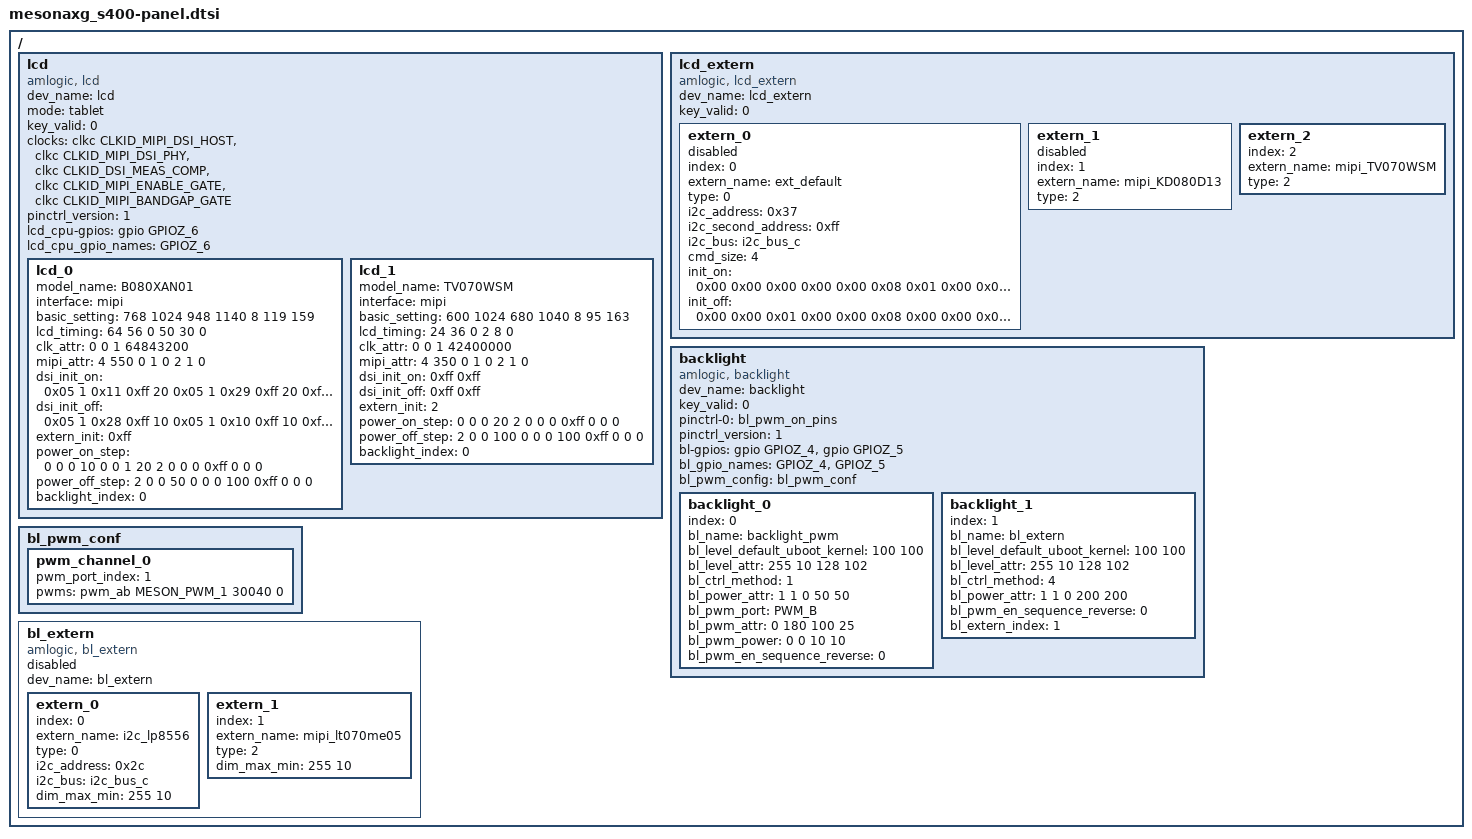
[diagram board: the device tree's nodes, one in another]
/*
 * arch/arm64/boot/dts/amlogic/mesongxm_q200-panel.dtsi
 *
 * Copyright (C) 2016 Amlogic, Inc. All rights reserved.
 *
 * This program is free software; you can redistribute it and/or modify
 * it under the terms of the GNU General Public License as published by
 * the Free Software Foundation; either version 2 of the License, or
 * (at your option) any later version.
 *
 * This program is distributed in the hope that it will be useful, but WITHOUT
 * ANY WARRANTY; without even the implied warranty of MERCHANTABILITY or
 * FITNESS FOR A PARTICULAR PURPOSE.  See the GNU General Public License for
 * more details.
 *
 */

/ {
	lcd{
		compatible = "amlogic, lcd";
		dev_name = "lcd";
		mode = "tablet";
		status = "okay";
		key_valid = <0>;
		clocks = <&clkc CLKID_MIPI_DSI_HOST
			&clkc CLKID_MIPI_DSI_PHY
			&clkc CLKID_DSI_MEAS_COMP
			&clkc CLKID_MIPI_ENABLE_GATE
			&clkc CLKID_MIPI_BANDGAP_GATE>;
		clock-names = "dsi_host",
			"dsi_phy",
			"dsi_meas",
			"mipi_enable_gate",
			"mipi_bandgap_gate";
		pinctrl_version = <1>; /* for uboot */

		/* power type:
		 *    (0=cpu_gpio, 1=pmu_gpio, 2=signal,3=extern, 0xff=ending)
		 * power index:
		 *    (point gpios_index, or extern_index,0xff=invalid)
		 * power value:(0=output low, 1=output high, 2=input)
		 * power delay:(unit in ms)
		 */
		lcd_cpu-gpios = <&gpio GPIOZ_6 GPIO_ACTIVE_HIGH>;
		lcd_cpu_gpio_names = "GPIOZ_6";

		lcd_0{
			model_name = "B080XAN01";
				/*interface(ttl,lvds,mipi)*/
			interface = "mipi";
				/* basic_setting:
				 * h_active,v_active,h_period,v_period,
				 * lcd_bits,screen_widht,screen_height
				 */
			basic_setting = <768 1024 948 1140 8 119 159>;
				/* lcd_timing:
				 * hs_width,hs_bp,hs_pol,vs_width,vs_bp,vs_pol
				 */
			lcd_timing = <64 56 0 50 30 0>;
				/* clk_attr:
				 * fr_adj_type(0=clock,1=htotal,2=vtotal),
				 * clk_ss_level,clk_auto_generate,
				 * pixel_clk(unit in Hz)
				 */
			clk_attr = <0 0 1 64843200>;
				/* mipi_attr:
				 * lane_num, bit_rate_max(MHz),
				 * factor(*100, default 0 for auto),
				 * operation_mode_init(0=video, 1=command),
				 * operation_mode_display(0=video, 1=command),
				 * video_mode_type
				 *     (0=sync_pulse,1=sync_event,2=burst),
				 * clk_lp_continuous(0=stop,1=continue),
				 * phy_stop_wait(0=auto,1=standard,2=slow)
				 */
			mipi_attr = <4 550 0 1 0 2 1 0>;
				/* dsi_init: data_type, num, data... */
			dsi_init_on = <0x05 1 0x11
					0xff 20     /* delay(ms) */
					0x05 1 0x29
					0xff 20     /* delay(ms) */
					0xff 0xff>; /* ending flag */
			dsi_init_off = <0x05 1 0x28
					0xff 10     /* delay(ms) */
					0x05 1 0x10
					0xff 10     /* delay(ms) */
					0xff 0xff>; /* ending flag */
				/* extern_init: 0xff for invalid */
			extern_init = <0xff>;
				/* power step: type,index,value,delay(ms) */
			power_on_step = <
					0 0 0 10
					0 0 1 20
					2 0 0 0
					0xff 0 0 0>;
			power_off_step = <2 0 0 50
					0 0 0 100
					0xff 0 0 0>;
			backlight_index = <0>;
		};

		lcd_1{
			model_name = "TV070WSM";
				/*interface(ttl,lvds,mipi)*/
			interface = "mipi";
				/* basic_setting:
				 * h_active,v_active,h_period,v_period,
				 * lcd_bits,screen_widht,screen_height
				 */
			basic_setting = <600 1024 680 1040 8 95 163>;
				/* lcd_timing:
				 * hs_width,hs_bp,hs_pol,vs_width,vs_bp,vs_pol
				 */
			lcd_timing = <24 36 0 2 8 0>;
				/* clk_attr:
				 * fr_adj_type(0=clock,1=htotal,2=vtotal),
				 * clk_ss_level,clk_auto_generate,
				 * pixel_clk(unit in Hz)
				 */
			clk_attr = <0 0 1 42400000>;
				/* mipi_attr:
				 * lane_num, bit_rate_max(MHz),
				 * factor(*100, default 0 for auto),
				 * operation_mode_init(0=video, 1=command),
				 * operation_mode_display(0=video, 1=command),
				 * video_mode_type
				 *     (0=sync_pulse,1=sync_event,2=burst),
				 * clk_lp_continuous(0=stop,1=continue),
				 * phy_stop_wait(0=auto,1=standard,2=slow)
				 */
			mipi_attr = <4 350 0 1 0 2 1 0>;
				/* dsi_init: data_type, num, data... */
			dsi_init_on = <0xff 0xff>; /* ending flag */
			dsi_init_off = <0xff 0xff>; /* ending flag */
				/* extern_init: 0xff for invalid */
			extern_init = <2>;
				/* power step: type,index,value,delay(ms) */
			power_on_step = <0 0 0 20
					2 0 0 0
					0xff 0 0 0>;
			power_off_step = <2 0 0 100
					0 0 0 100
					0xff 0 0 0>;
			backlight_index = <0>;
		};
	};

	lcd_extern{
		compatible = "amlogic, lcd_extern";
		dev_name = "lcd_extern";
		status = "okay";
		key_valid = <0>;

		extern_0{
			index = <0>;
			extern_name = "ext_default";
			status = "disabled";
			type = <0>; /* 0=i2c, 1=spi, 2=mipi */
			i2c_address = <0x37>; /* 7bit i2c address */
			/* 7bit i2c address, 0xff for none */
			i2c_second_address = <0xff>;
			i2c_bus = "i2c_bus_c";
			cmd_size = <4>;
			/* init on/off: (type, value..., delay),
			 * must match cmd_size for every group
			 * type: 0x00=cmd(bit[3:0]=1 for second_addr),
			 *		0x10=gpio, 0xff=ending
			 * value: i2c or spi cmd, or gpio index & level,
			 *		fill 0x0 for no use
			 * delay: unit ms
			 */
			init_on = <0x00 0x00 0x00 0x00
						0x00 0x08 0x01 0x00
						0x00 0x10 0x3F 0x00
						0x00 0x11 0x00 0x00
						0x00 0x12 0x00 0x00
						0x00 0x13 0xE4 0x00
						0x00 0x14 0x02 0x00
						0x00 0x15 0x02 0x00
						0x00 0x16 0x24 0x00
						0x00 0x17 0x00 0x00
						0x00 0x18 0x21 0x00
						0x00 0x20 0x3F 0x00
						0x00 0x21 0xFF 0x00
						0x00 0x22 0x00 0x00
						0x00 0x23 0x00 0x00
						0x00 0x24 0x00 0x00
						0x00 0x25 0x00 0x00
						0x00 0x26 0xE4 0x00
						0x00 0x27 0x00 0x00
						0x00 0x28 0x28 0x00
						0x00 0x29 0x01 0x00
						0x00 0x2A 0x00 0x00
						0x00 0x2B 0x01 0x00
						0x00 0x2C 0x0E 0x00
						0x00 0x2D 0x00 0x00
						0x00 0x2E 0x18 0x00
						0x00 0x2F 0x02 0x00
						0x00 0x30 0x02 0x00
						0x00 0x31 0x00 0x00
						0x00 0x32 0x63 0x00
						0x00 0x40 0x00 0x00
						0x00 0x41 0x00 0x00
						0x00 0x42 0x00 0x00
						0x00 0x12 0x00 0x00
						0x00 0x13 0xE4 0x00
						0x00 0x14 0x02 0x00
						0x00 0x15 0x00 0x00
						0x00 0x16 0x0D 0x00
						0x00 0x17 0x00 0x00
						0x00 0x18 0x21 0x00
						0x00 0x41 0x06 0x00
						0x00 0x00 0x01 0x00
						0x00 0x08 0x00 0x00
						0x00 0x10 0x00 0x00
						0x00 0x11 0x0F 0x00
						0xff 0x00 0x00 0x00>;
			init_off = <0x00 0x00 0x01 0x00
						0x00 0x08 0x00 0x00
						0x00 0x10 0x00 0x00
						0x00 0x11 0x0F 0x00
						0xff 0x00 0x00 0x00>;
		};

		extern_1{
			index = <1>;
			extern_name = "mipi_KD080D13";
			status = "disabled";
			type = <2>; /* 0=i2c, 1=spi, 2=mipi */
		};

		extern_2{
			index = <2>;
			extern_name = "mipi_TV070WSM";
			status = "okay";
			type = <2>; /* 0=i2c, 1=spi, 2=mipi */
		};
	};

	backlight{
		compatible = "amlogic, backlight";
		dev_name = "backlight";
		status = "okay";
		key_valid = <0>;
		pinctrl-names = "pwm_on";
		pinctrl-0 = <&bl_pwm_on_pins>;
		pinctrl_version = <1>; /* for uboot */
		/* power index:(point gpios_index, 0xff=invalid)
		 * power value:(0=output low, 1=output high, 2=input)
		 * power delay:(unit in ms)
		 */
		bl-gpios = <&gpio GPIOZ_4 GPIO_ACTIVE_HIGH
			&gpio GPIOZ_5 GPIO_ACTIVE_HIGH>;
		bl_gpio_names = "GPIOZ_4","GPIOZ_5";
		bl_pwm_config = <&bl_pwm_conf>;

		backlight_0{
			index = <0>;
			bl_name = "backlight_pwm";
			bl_level_default_uboot_kernel = <100 100>;
				/* level_attr: max, min, mid, mid_mapping */
			bl_level_attr = <255 10 128 102>;

			/* 1=pwm, 2=pwm_combo, 3=ldim, 4=extern */
			bl_ctrl_method = <1>;
				/* power_attr:
				 * en_gpio_index, on_value, off_value,
				 * on_delay(ms), off_delay(ms)
				 */
			bl_power_attr = <1 1 0 50 50>;
				/* pwm_port: PWM_A,PWM_B,PWM_C,PWM_D,PWM_VS */
			bl_pwm_port = "PWM_B";
				/* pwm_attr:
				 * pwm_method: 0=negative, 1=positive
				 * pwm_freq: pwm_vs: 1~4(vfreq multiple),
				 *           other pwm: real freq(Hz)
				 * duty_max(%), duty_min(%)
				 */
			bl_pwm_attr = <0 180 100 25>;
				/* pwm_power:
				 * pwm_gpio_index, pwm_gpio_off,
				 * pwm_on_delay(ms), pwm_off_delay(ms)
				 */
			bl_pwm_power = <0 0 10 10>;
			bl_pwm_en_sequence_reverse = <0>; /* 1 for reverse */
		};
		backlight_1{
			index = <1>;
			bl_name = "bl_extern";
			bl_level_default_uboot_kernel = <100 100>;
				/* level_attr: max, min, mid, mid_mapping */
			bl_level_attr = <255 10 128 102>;

			/* 1=pwm, 2=pwm_combo, 3=ldim, 4=extern */
			bl_ctrl_method = <4>;
				/* power_attr:
				 * en_gpio_index, on_value, off_value,
				 * on_delay(ms), off_delay(ms)
				 */
			bl_power_attr = <1 1 0 200 200>;
			bl_pwm_en_sequence_reverse = <0>; /* 1 for reverse */
			bl_extern_index = <1>;
		};
	};

	bl_pwm_conf:bl_pwm_conf{
		pwm_channel_0 {
			pwm_port_index = <1>;
			pwms = <&pwm_ab MESON_PWM_1 30040 0>;
		};
	};

	bl_extern{
		compatible = "amlogic, bl_extern";
		dev_name = "bl_extern";
		status = "disabled";

		extern_0{
			index = <0>;
			extern_name = "i2c_lp8556";

			/*bl_extern_driver type: 0=i2c, 1=spi, 2=mipi*/
			type = <0>;
			i2c_address = <0x2c>; /** 7bit i2c address */
			i2c_bus = "i2c_bus_c";
			dim_max_min = <255 10>;
		};

		extern_1{
			index = <1>;
			extern_name = "mipi_lt070me05";

			/*bl_extern_driver type: 0=i2c, 1=spi, 2=mipi*/
			type = <2>;
			dim_max_min = <255 10>;
		};
	};


};/* end of panel */

